AUTOSAR XML (schema 00047)
package /ETAS_BIP
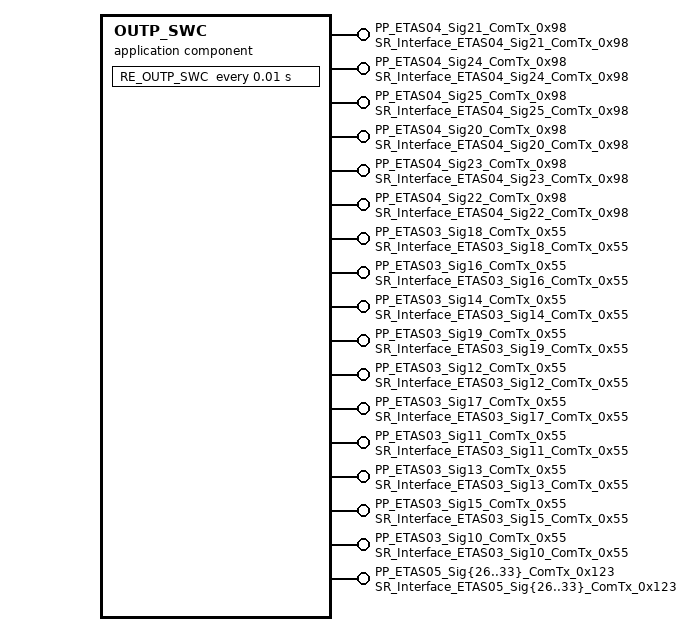
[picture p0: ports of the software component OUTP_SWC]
  application sw component type OUTP_SWC
    24 x provide port:
      PP_ETAS04_Sig21_ComTx_0x98: provided-interface=SR_Interface_ETAS04_Sig21_ComTx_0x98
      PP_ETAS04_Sig24_ComTx_0x98: provided-interface=SR_Interface_ETAS04_Sig24_ComTx_0x98
      PP_ETAS04_Sig25_ComTx_0x98: provided-interface=SR_Interface_ETAS04_Sig25_ComTx_0x98
      PP_ETAS04_Sig20_ComTx_0x98: provided-interface=SR_Interface_ETAS04_Sig20_ComTx_0x98
      PP_ETAS04_Sig23_ComTx_0x98: provided-interface=SR_Interface_ETAS04_Sig23_ComTx_0x98
      PP_ETAS04_Sig22_ComTx_0x98: provided-interface=SR_Interface_ETAS04_Sig22_ComTx_0x98
      PP_ETAS03_Sig18_ComTx_0x55: provided-interface=SR_Interface_ETAS03_Sig18_ComTx_0x55
      PP_ETAS03_Sig16_ComTx_0x55: provided-interface=SR_Interface_ETAS03_Sig16_ComTx_0x55
      PP_ETAS03_Sig14_ComTx_0x55: provided-interface=SR_Interface_ETAS03_Sig14_ComTx_0x55
      PP_ETAS03_Sig19_ComTx_0x55: provided-interface=SR_Interface_ETAS03_Sig19_ComTx_0x55
      PP_ETAS03_Sig12_ComTx_0x55: provided-interface=SR_Interface_ETAS03_Sig12_ComTx_0x55
      PP_ETAS03_Sig17_ComTx_0x55: provided-interface=SR_Interface_ETAS03_Sig17_ComTx_0x55
      PP_ETAS03_Sig11_ComTx_0x55: provided-interface=SR_Interface_ETAS03_Sig11_ComTx_0x55
      PP_ETAS03_Sig13_ComTx_0x55: provided-interface=SR_Interface_ETAS03_Sig13_ComTx_0x55
      PP_ETAS03_Sig15_ComTx_0x55: provided-interface=SR_Interface_ETAS03_Sig15_ComTx_0x55
      PP_ETAS03_Sig10_ComTx_0x55: provided-interface=SR_Interface_ETAS03_Sig10_ComTx_0x55
      PP_ETAS05_Sig{26..33}_ComTx_0x123: provided-interface=SR_Interface_ETAS05_Sig{26..33}_ComTx_0x123
    behavior IB_OUTP_SWC
      timing event TE_OUTP_SWC_10ms: start-on-event=RE_OUTP_SWC, period=0.01
      runnable RE_OUTP_SWC
        data-send-points:
          14 x access:
            DSP_ETAS04_Sig21_ComTx_0x98_0: accessed-variable=PP_ETAS04_Sig21_ComTx_0x98.ETAS04_Sig21_ComTx_0x98
            DSP_ETAS04_Sig22_ComTx_0x98_0: accessed-variable=PP_ETAS04_Sig22_ComTx_0x98.ETAS04_Sig22_ComTx_0x98
            DSP_ETAS04_Sig25_ComTx_0x98_0: accessed-variable=PP_ETAS04_Sig25_ComTx_0x98.ETAS04_Sig25_ComTx_0x98
            DSP_ETAS04_Sig20_ComTx_0x98_0: accessed-variable=PP_ETAS04_Sig20_ComTx_0x98.ETAS04_Sig20_ComTx_0x98
            DSP_ETAS04_Sig24_ComTx_0x98_0: accessed-variable=PP_ETAS04_Sig24_ComTx_0x98.ETAS04_Sig24_ComTx_0x98
            DSP_ETAS04_Sig23_ComTx_0x98_0: accessed-variable=PP_ETAS04_Sig23_ComTx_0x98.ETAS04_Sig23_ComTx_0x98
            DSP_ETAS05_Sig{26..33}_ComTx_0x123_0: accessed-variable=PP_ETAS05_Sig{26..33}_ComTx_0x123.ETAS05_Sig{26..33}_ComTx_0x123
        data-write-access:
          10 x access:
            DWA_ETAS03_Sig10_ComTx_0x55_0: accessed-variable=PP_ETAS03_Sig10_ComTx_0x55.ETAS03_Sig10_ComTx_0x55
            DWA_ETAS03_Sig18_ComTx_0x55_0: accessed-variable=PP_ETAS03_Sig18_ComTx_0x55.ETAS03_Sig18_ComTx_0x55
            DWA_ETAS03_Sig13_ComTx_0x55_0: accessed-variable=PP_ETAS03_Sig13_ComTx_0x55.ETAS03_Sig13_ComTx_0x55
            DWA_ETAS03_Sig15_ComTx_0x55_0: accessed-variable=PP_ETAS03_Sig15_ComTx_0x55.ETAS03_Sig15_ComTx_0x55
            DWA_ETAS03_Sig19_ComTx_0x55_0: accessed-variable=PP_ETAS03_Sig19_ComTx_0x55.ETAS03_Sig19_ComTx_0x55
            DWA_ETAS03_Sig12_ComTx_0x55_0: accessed-variable=PP_ETAS03_Sig12_ComTx_0x55.ETAS03_Sig12_ComTx_0x55
            DWA_ETAS03_Sig17_ComTx_0x55_0: accessed-variable=PP_ETAS03_Sig17_ComTx_0x55.ETAS03_Sig17_ComTx_0x55
            DWA_ETAS03_Sig14_ComTx_0x55_0: accessed-variable=PP_ETAS03_Sig14_ComTx_0x55.ETAS03_Sig14_ComTx_0x55
            DWA_ETAS03_Sig16_ComTx_0x55_0: accessed-variable=PP_ETAS03_Sig16_ComTx_0x55.ETAS03_Sig16_ComTx_0x55
            DWA_ETAS03_Sig11_ComTx_0x55_0: accessed-variable=PP_ETAS03_Sig11_ComTx_0x55.ETAS03_Sig11_ComTx_0x55
